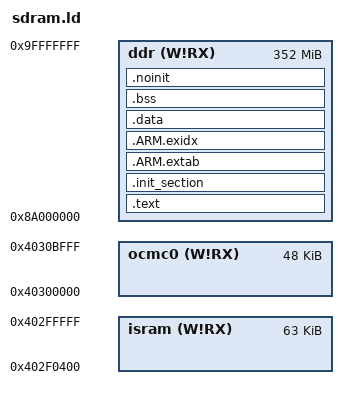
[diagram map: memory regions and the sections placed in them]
/****************************************************************************
 * boards/arm/am335x/beaglebone-black/scripts/sdram.ld
 *
 * Licensed to the Apache Software Foundation (ASF) under one or more
 * contributor license agreements.  See the NOTICE file distributed with
 * this work for additional information regarding copyright ownership.  The
 * ASF licenses this file to you under the Apache License, Version 2.0 (the
 * "License"); you may not use this file except in compliance with the
 * License.  You may obtain a copy of the License at
 *
 *   http://www.apache.org/licenses/LICENSE-2.0
 *
 * Unless required by applicable law or agreed to in writing, software
 * distributed under the License is distributed on an "AS IS" BASIS, WITHOUT
 * WARRANTIES OR CONDITIONS OF ANY KIND, either express or implied.  See the
 * License for the specific language governing permissions and limitations
 * under the License.
 *
 ****************************************************************************/

/* The Beaglebone Black and 512MB of SDRAM beginning at virtual address
 * 0x8000:0000. Execution begins at address 0x8a00000, leaving 352MB for NuttX.
 *
 * Vectors in low memory are assumed and 16KB of OCMC0 is reserved at the
 * high end of OCMC0 for the page table.
 */

MEMORY
{
    isram (W!RX) : ORIGIN = 0x402F0400, LENGTH = 63K
    ocmc0 (W!RX) : ORIGIN = 0x40300000, LENGTH = 64K -16K
    ddr   (W!RX) : ORIGIN = 0x8a000000, LENGTH = 512M - 160M
}

ENTRY(entry)
ENTRY(_stext)

SECTIONS
{
    .text :
    {
        _stext = ABSOLUTE(.);
        *(.vectors)
        *(.text .text.*)
        *(.fixup)
        *(.gnu.warning)
        *(.rodata .rodata.*)
        *(.gnu.linkonce.t.*)
        *(.glue_7)
        *(.glue_7t)
        *(.got)
        *(.gcc_except_table)
        *(.gnu.linkonce.r.*)
        *(.ARM.extab*)
        *(.gnu.linkonce.armextab.*)
        _etext = ABSOLUTE(.);
    } > ddr

    .init_section :
    {
        _sinit = ABSOLUTE(.);
        KEEP(*(.init_array .init_array.*))
        _einit = ABSOLUTE(.);
    } > ddr

    .ARM.extab :
    {
        *(.ARM.extab*)
    } > ddr

    /* .ARM.exidx is sorted, so has to go in its own output section.  */

    PROVIDE_HIDDEN (__exidx_start = .);
    .ARM.exidx :
    {
        *(.ARM.exidx* .gnu.linkonce.armexidx.*)
    } > ddr
    PROVIDE_HIDDEN (__exidx_end = .);

    .data :
    {
        _sdata = ABSOLUTE(.);
        *(.data .data.*)
        *(.gnu.linkonce.d.*)
        CONSTRUCTORS
        . = ALIGN(4);
        _edata = ABSOLUTE(.);
    } > ddr

    .bss :
    {
        _sbss = ABSOLUTE(.);
        *(.bss .bss.*)
        *(.gnu.linkonce.b.*)
        *(COMMON)
        . = ALIGN(4);
        _ebss = ABSOLUTE(.);
    } > ddr

    /* Uninitialized data */

    .noinit :
    {
        _snoinit = ABSOLUTE(.);
        *(.noinit*)
        _enoinit = ABSOLUTE(.);
    } > ddr

    /* Stabs debugging sections. */

    .stab 0 : { *(.stab) }
    .stabstr 0 : { *(.stabstr) }
    .stab.excl 0 : { *(.stab.excl) }
    .stab.exclstr 0 : { *(.stab.exclstr) }
    .stab.index 0 : { *(.stab.index) }
    .stab.indexstr 0 : { *(.stab.indexstr) }
    .comment 0 : { *(.comment) }
    .debug_abbrev 0 : { *(.debug_abbrev) }
    .debug_info 0 : { *(.debug_info) }
    .debug_line 0 : { *(.debug_line) }
    .debug_pubnames 0 : { *(.debug_pubnames) }
    .debug_aranges 0 : { *(.debug_aranges) }
}
